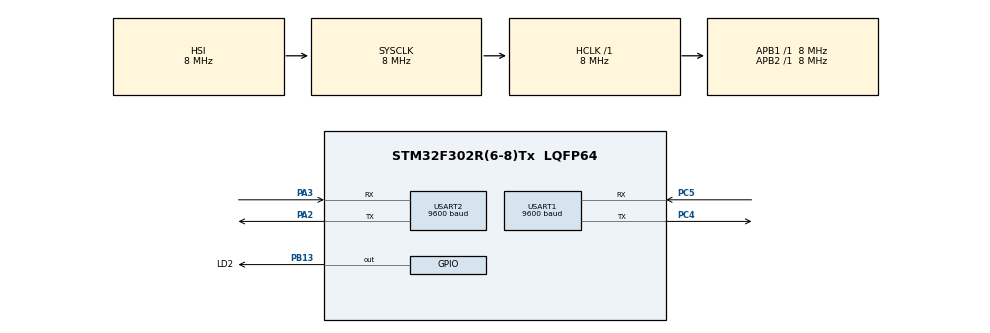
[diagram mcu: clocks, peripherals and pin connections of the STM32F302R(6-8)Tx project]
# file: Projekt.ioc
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Mcu.Family=STM32F3
Mcu.Name=STM32F302R(6-8)Tx
Mcu.Package=LQFP64
NVIC.PriorityGroup=NVIC_PRIORITYGROUP_4
NVIC.USART1_IRQn=true\:0\:0\:false\:false\:true\:true\:true\:true
NVIC.USART2_IRQn=true\:0\:0\:false\:false\:true\:true\:true\:true
PA2.Mode=Asynchronous
PA2.Signal=USART2_TX
PA3.Mode=Asynchronous
PA3.Signal=USART2_RX
PB13.GPIO_Label=LD2
PB13.Signal=GPIO_Output
PC4.Mode=Asynchronous
PC4.Signal=USART1_TX
PC5.Mode=Asynchronous
PC5.Signal=USART1_RX
ProjectManager.HeapSize=0x200
ProjectManager.StackSize=0x400
ProjectManager.TargetToolchain=STM32CubeIDE
RCC.AHBFreq_Value=8000000
RCC.APB1Freq_Value=8000000
RCC.APB2Freq_Value=8000000
RCC.CortexFreq_Value=8000000
RCC.HSE_VALUE=8000000
RCC.HSI_VALUE=8000000
RCC.LSE_VALUE=32768
RCC.SYSCLKFreq_VALUE=8000000
USART1.BaudRate=9600
USART1.VirtualMode-Asynchronous=VM_ASYNC
USART2.BaudRate=9600
USART2.VirtualMode-Asynchronous=VM_ASYNC
board=custom

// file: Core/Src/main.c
/* USER CODE BEGIN Header */
/**
  ******************************************************************************
  * @file           : main.c
  * @brief          : Main program body
  ******************************************************************************
  * @attention
  *
  * Copyright (c) 2024 STMicroelectronics.
  * All rights reserved.
  *
  * This software is licensed under terms that can be found in the LICENSE file
  * in the root directory of this software component.
  * If no LICENSE file comes with this software, it is provided AS-IS.
  *
  ******************************************************************************
  */
/* USER CODE END Header */
#include "main.h"
#include "string.h"

UART_HandleTypeDef huart1;
UART_HandleTypeDef huart2;

/* USER CODE BEGIN PV */

uint8_t rx_buffer[50];
uint8_t tx_buffer[] = "Button Pressed!\r\n";

/* USER CODE END PV */

void SystemClock_Config(void);
static void MX_GPIO_Init(void);
static void MX_USART2_UART_Init(void);
static void MX_USART1_UART_Init(void);

int main(void)
{

  /* MCU Configuration--------------------------------------------------------*/

  /* Reset of all peripherals, Initializes the Flash interface and the Systick. */
  HAL_Init();

  /* Configure the system clock */
  SystemClock_Config();

  /* Initialize all configured peripherals */
  MX_GPIO_Init();
  MX_USART2_UART_Init();
  MX_USART1_UART_Init();

  /* Infinite loop */
  while (1)
  {
	  if (HAL_GPIO_ReadPin(GPIOC, GPIO_PIN_13) == GPIO_PIN_RESET)
	      {
	          // Transmit a message to UART1
	          uint8_t tx_message[] = "Button Pressed\r\n";
	          HAL_UART_Transmit(&huart1, tx_message, strlen((char *)tx_message), HAL_MAX_DELAY);

	          HAL_Delay(200);
	      }

	      // Check if any data is received on UART2
	      if (HAL_UART_Receive(&huart2, rx_buffer, sizeof(rx_buffer), 2000) == HAL_OK)
	      {

	          HAL_GPIO_WritePin(LD2_GPIO_Port, LD2_Pin, GPIO_PIN_SET);
	          HAL_Delay(500); // Keep LED ON for 500ms
	          HAL_GPIO_WritePin(LD2_GPIO_Port, LD2_Pin, GPIO_PIN_RESET);

	          memset(rx_buffer, 0, sizeof(rx_buffer));
	      }
  }
}

void SystemClock_Config(void)
{
  RCC_OscInitTypeDef RCC_OscInitStruct = {0};
  RCC_ClkInitTypeDef RCC_ClkInitStruct = {0};
  RCC_PeriphCLKInitTypeDef PeriphClkInit = {0};

  /** Initializes the RCC Oscillators according to the specified parameters
  * in the RCC_OscInitTypeDef structure.
  */
  RCC_OscInitStruct.OscillatorType = RCC_OSCILLATORTYPE_HSI;
  RCC_OscInitStruct.HSIState = RCC_HSI_ON;
  RCC_OscInitStruct.HSICalibrationValue = RCC_HSICALIBRATION_DEFAULT;
  RCC_OscInitStruct.PLL.PLLState = RCC_PLL_NONE;
  if (HAL_RCC_OscConfig(&RCC_OscInitStruct) != HAL_OK)
  {
    Error_Handler();
  }

  /** Initializes the CPU, AHB and APB buses clocks
  */
  RCC_ClkInitStruct.ClockType = RCC_CLOCKTYPE_HCLK|RCC_CLOCKTYPE_SYSCLK
                              |RCC_CLOCKTYPE_PCLK1|RCC_CLOCKTYPE_PCLK2;
  RCC_ClkInitStruct.SYSCLKSource = RCC_SYSCLKSOURCE_HSI;
  RCC_ClkInitStruct.AHBCLKDivider = RCC_SYSCLK_DIV1;
  RCC_ClkInitStruct.APB1CLKDivider = RCC_HCLK_DIV1;
  RCC_ClkInitStruct.APB2CLKDivider = RCC_HCLK_DIV1;

  if (HAL_RCC_ClockConfig(&RCC_ClkInitStruct, FLASH_LATENCY_0) != HAL_OK)
  {
    Error_Handler();
  }
  PeriphClkInit.PeriphClockSelection = RCC_PERIPHCLK_USART1;
  PeriphClkInit.Usart1ClockSelection = RCC_USART1CLKSOURCE_PCLK1;
  if (HAL_RCCEx_PeriphCLKConfig(&PeriphClkInit) != HAL_OK)
  {
    Error_Handler();
  }
}

static void MX_USART1_UART_Init(void)
{

  huart1.Instance = USART1;
  huart1.Init.BaudRate = 9600;
  huart1.Init.WordLength = UART_WORDLENGTH_8B;
  huart1.Init.StopBits = UART_STOPBITS_1;
  huart1.Init.Parity = UART_PARITY_NONE;
  huart1.Init.Mode = UART_MODE_TX_RX;
  huart1.Init.HwFlowCtl = UART_HWCONTROL_NONE;
  huart1.Init.OverSampling = UART_OVERSAMPLING_16;
  huart1.Init.OneBitSampling = UART_ONE_BIT_SAMPLE_DISABLE;
  huart1.AdvancedInit.AdvFeatureInit = UART_ADVFEATURE_NO_INIT;
  if (HAL_UART_Init(&huart1) != HAL_OK)
  {
    Error_Handler();
  }

}

static void MX_USART2_UART_Init(void)
{

  huart2.Instance = USART2;
  huart2.Init.BaudRate = 9600;
  huart2.Init.WordLength = UART_WORDLENGTH_8B;
  huart2.Init.StopBits = UART_STOPBITS_1;
  huart2.Init.Parity = UART_PARITY_NONE;
  huart2.Init.Mode = UART_MODE_TX_RX;
  huart2.Init.HwFlowCtl = UART_HWCONTROL_NONE;
  huart2.Init.OverSampling = UART_OVERSAMPLING_16;
  huart2.Init.OneBitSampling = UART_ONE_BIT_SAMPLE_DISABLE;
  huart2.AdvancedInit.AdvFeatureInit = UART_ADVFEATURE_NO_INIT;
  if (HAL_UART_Init(&huart2) != HAL_OK)
  {
    Error_Handler();
  }

}

static void MX_GPIO_Init(void)
{
  GPIO_InitTypeDef GPIO_InitStruct = {0};

  /* GPIO Ports Clock Enable */
  __HAL_RCC_GPIOC_CLK_ENABLE();
  __HAL_RCC_GPIOF_CLK_ENABLE();
  __HAL_RCC_GPIOA_CLK_ENABLE();
  __HAL_RCC_GPIOB_CLK_ENABLE();

  /*Configure GPIO pin Output Level */
  HAL_GPIO_WritePin(LD2_GPIO_Port, LD2_Pin, GPIO_PIN_RESET);

  /*Configure GPIO pin : PC13 */
  GPIO_InitStruct.Pin = GPIO_PIN_13;
  GPIO_InitStruct.Mode = GPIO_MODE_IT_RISING;
  GPIO_InitStruct.Pull = GPIO_NOPULL;
  HAL_GPIO_Init(GPIOC, &GPIO_InitStruct);

  /*Configure GPIO pin : LD2_Pin */
  GPIO_InitStruct.Pin = LD2_Pin;
  GPIO_InitStruct.Mode = GPIO_MODE_OUTPUT_PP;
  GPIO_InitStruct.Pull = GPIO_NOPULL;
  GPIO_InitStruct.Speed = GPIO_SPEED_FREQ_LOW;
  HAL_GPIO_Init(LD2_GPIO_Port, &GPIO_InitStruct);

  /* EXTI interrupt init*/
  HAL_NVIC_SetPriority(EXTI15_10_IRQn, 0, 0);
  HAL_NVIC_EnableIRQ(EXTI15_10_IRQn);

}

void Error_Handler(void)
{
  __disable_irq();
  while (1)
  {
  }
}
